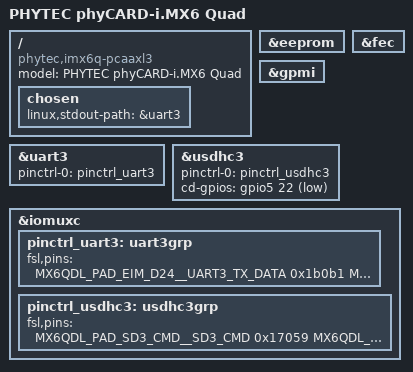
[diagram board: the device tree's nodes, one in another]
// SPDX-License-Identifier: (GPL-2.0+ OR MIT)
/*
 * Copyright (C) 2014 PHYTEC Messtechnik GmbH
 * Author: Christian Hemp <c.hemp@phytec.de>
 */

/dts-v1/;
#include "imx6qdl-phytec-phycard-som.dtsi"

/ {
	model = "PHYTEC phyCARD-i.MX6 Quad";
	compatible = "phytec,imx6q-pcaaxl3", "fsl,imx6q";

	chosen {
		linux,stdout-path = &uart3;
	};
};

&eeprom {
	status = "okay";
};

&fec {
	status = "okay";
};

&gpmi {
	status = "okay";
};

&uart3 {
	pinctrl-names = "default";
	pinctrl-0 = <&pinctrl_uart3>;
	status = "okay";
};

&usdhc3 {
        pinctrl-names = "default";
        pinctrl-0 = <&pinctrl_usdhc3>;
        cd-gpios = <&gpio5 22 GPIO_ACTIVE_LOW>;
        status = "okay";
};

&iomuxc {
	pinctrl_uart3: uart3grp {
		fsl,pins = <
			MX6QDL_PAD_EIM_D24__UART3_TX_DATA	0x1b0b1
			MX6QDL_PAD_EIM_D25__UART3_RX_DATA	0x1b0b1
		>;
	};

	pinctrl_usdhc3: usdhc3grp {
		fsl,pins = <
			MX6QDL_PAD_SD3_CMD__SD3_CMD		0x17059
			MX6QDL_PAD_SD3_CLK__SD3_CLK		0x10059
			MX6QDL_PAD_SD3_DAT0__SD3_DATA0		0x17059
			MX6QDL_PAD_SD3_DAT1__SD3_DATA1		0x17059
			MX6QDL_PAD_SD3_DAT2__SD3_DATA2		0x17059
			MX6QDL_PAD_SD3_DAT3__SD3_DATA3		0x17059
			MX6QDL_PAD_CSI0_DAT4__GPIO5_IO22	0x1b0b0
		>;
	};
};
